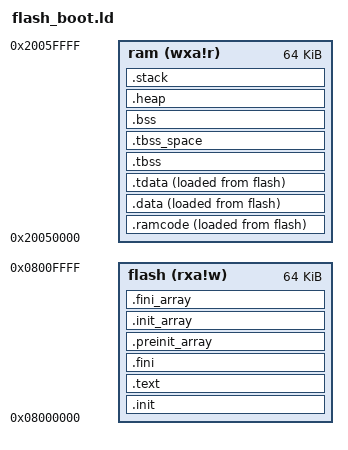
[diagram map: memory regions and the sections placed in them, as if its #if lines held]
/**
 ******************************************************************************
 * @file      gcc_riscv32.ld
 * @author    ListenAI application team
 * @brief     Linker script
 *                      8Mbytes     FLASH
 *                      16Kbytes    DTCMRAM
 *                      16Kbytes    ITCMRAM
 *                      128Kbytes   RAM
 *
 *            Set heap size, stack size and stack location according
 *            to application requirements.
 *
 *            Set memory bank area and size if external memory is used
 ******************************************************************************
 * @attentionsss
 *
 * <h2><center>&copy; Copyright (c) 2021 ListenAI.
 * All rights reserved.</center></h2>
 *
 * This software component is licensed by ListenAI under BSD 3-Clause license,
 * the "License"; You may not use this file except in compliance with the
 * License. You may obtain a copy of the License at:
 *                        opensource.org/licenses/BSD-3-Clause
 *
 ******************************************************************************
 */

OUTPUT_ARCH( "riscv" )

ENTRY( _start )

#if FLASH_ENC_ALL==1
FLASH_BASE = 0x08000000;
#else
FLASH_BASE = 0x30000000;
#endif

MEMORY
{
  flash (rxa!w) : ORIGIN = FLASH_BASE, LENGTH = 64K
  ram (wxa!r) : ORIGIN = 0x20050000, LENGTH = 64K
}

REGION_ALIAS("ROM", flash)
REGION_ALIAS("RAM", ram)
REGION_ALIAS("DATA_LMA", flash)

SECTIONS
{
  /* To provide symbol __STACK_SIZE, __HEAP_SIZE and __SMP_CPU_CNT */
  PROVIDE(__STACK_SIZE = 4K);
  PROVIDE(__HEAP_SIZE = 4K);
  PROVIDE(__SMP_CPU_CNT = 1);
  __TOT_STACK_SIZE = __STACK_SIZE * __SMP_CPU_CNT;

  .init           :
  {
    KEEP(*(.OTA_HEADER)) /* OTA header */
    KEEP(*(.SIGN_DATA))  /* signature data */
    . = ALIGN(512);
    /* vector table locate at ROM */
    *(.vtable)
    *(.vtable_s)
    KEEP (*(SORT_NONE(.init)))
    . = ALIGN(4);
  } >ROM AT>ROM

  /* Code section located at ROM */
  .text           :
  {
    *(.text.unlikely .text.unlikely.*)
    *(.text.startup .text.startup.*)
    *(.text .text.*)
    *(.gnu.linkonce.t.*)
    /* readonly data placed in ROM */
    . = ALIGN(8);
    *(.srodata.cst16)
    *(.srodata.cst8)
    *(.srodata.cst4)
    *(.srodata.cst2)
    *(.srodata .srodata.*)
    *(.rdata)
    *(.ROM_DATA)
    *(.gnu.linkonce.r.*)
    /* below sections are used for rt-thread */
    . = ALIGN(4);
    __rt_init_start = .;
    KEEP(*(SORT(.rti_fn*)))
    __rt_init_end = .;
    . = ALIGN(4);
    __fsymtab_start = .;
    KEEP(*(FSymTab))
    __fsymtab_end = .;
    . = ALIGN(4);
    __vsymtab_start = .;
    KEEP(*(VSymTab))
    __vsymtab_end = .;
  } >ROM AT>ROM

  .fini           :
  {
    KEEP (*(SORT_NONE(.fini)))
  } >ROM AT>ROM

  .preinit_array  :
  {
    PROVIDE_HIDDEN (__preinit_array_start = .);
    KEEP (*(.preinit_array))
    PROVIDE_HIDDEN (__preinit_array_end = .);
  } >ROM AT>ROM

  .init_array     :
  {
    PROVIDE_HIDDEN (__init_array_start = .);
    KEEP (*(SORT_BY_INIT_PRIORITY(.init_array.*) SORT_BY_INIT_PRIORITY(.ctors.*)))
    KEEP (*(.init_array EXCLUDE_FILE (*crtbegin.o *crtbegin?.o *crtend.o *crtend?.o ) .ctors))
    PROVIDE_HIDDEN (__init_array_end = .);
  } >ROM AT>ROM

  .fini_array     :
  {
    PROVIDE_HIDDEN (__fini_array_start = .);
    KEEP (*(SORT_BY_INIT_PRIORITY(.fini_array.*) SORT_BY_INIT_PRIORITY(.dtors.*)))
    KEEP (*(.fini_array EXCLUDE_FILE (*crtbegin.o *crtbegin?.o *crtend.o *crtend?.o ) .dtors))
    PROVIDE_HIDDEN (__fini_array_end = .);
  } >ROM AT>ROM

  PROVIDE(_rom_code_start = ORIGIN(ROM));
  PROVIDE(_rom_code_end   = .);
  .ramcode        : ALIGN(8)
  {
    *(.rodata .rodata.*)
    . = ALIGN(8);
  } >RAM AT>DATA_LMA

  PROVIDE( _ram_code_start = ADDR(.ramcode));
  PROVIDE( _ram_code_end  = .);
  PROVIDE( _ilm_lma = LOADADDR(.text) );
  PROVIDE( _ilm = ADDR(.text) );
  PROVIDE( _eilm = . );
  PROVIDE( _text_lma = LOADADDR(.ramcode) );
  PROVIDE( _text = ADDR(.ramcode) );
  PROVIDE (_etext = .);
  PROVIDE (__etext = .);
  PROVIDE (etext = .);

  .data            : ALIGN(8)
  {
    KEEP(*(.data.ctest*))
    *(.data .data.*)
    *(.gnu.linkonce.d.*)
    . = ALIGN(8);
    PROVIDE( __global_pointer$ = . + 0x800 );
    *(.sdata .sdata.* .sdata*)
    *(.gnu.linkonce.s.*)
    /* readonly data placed in RAM for access speed */
    . = ALIGN(8);
    *(.gnu.linkonce.r.*)
    /* below sections are used for rt-thread */
    . = ALIGN(4);
    __rt_init_start = .;
    KEEP(*(SORT(.rti_fn*)))
    __rt_init_end = .;
    . = ALIGN(4);
    __fsymtab_start = .;
    KEEP(*(FSymTab))
    __fsymtab_end = .;
    . = ALIGN(4);
    __vsymtab_start = .;
    KEEP(*(VSymTab))
    __vsymtab_end = .;
    . = ALIGN(8);
  } >RAM AT>DATA_LMA

  .tdata           : ALIGN(8)
  {
    PROVIDE( __tls_base = . );
    *(.tdata .tdata.* .gnu.linkonce.td.*)
  } >RAM AT>DATA_LMA

  PROVIDE( _data_lma = LOADADDR(.data) );
  PROVIDE( _data = ADDR(.data) );
  PROVIDE( _edata = . );
  PROVIDE( edata = . );

  PROVIDE( _fbss = . );
  PROVIDE( __bss_start = . );

  .tbss (NOLOAD)   : ALIGN(8)
  {
    *(.tbss .tbss.* .gnu.linkonce.tb.*)
    *(.tcommon)
    PROVIDE( __tls_end = . );
  } >RAM AT>RAM

  .tbss_space (NOLOAD) : ALIGN(8)
  {
    . = . + SIZEOF(.tbss);
  } >RAM AT>RAM

  .bss (NOLOAD)   : ALIGN(8)
  {
    *(.sbss*)
    *(.gnu.linkonce.sb.*)
    *(.bss .bss.*)
    *(.gnu.linkonce.b.*)
    *(COMMON)
    . = ALIGN(4);
  } >RAM AT>RAM

  PROVIDE( _end = . );
  PROVIDE( end = . );

  /* Nuclei C Runtime Library requirements:
   * 1. heap need to be align at 16 bytes
   * 2. __heap_start and __heap_end symbol need to be defined
   * 3. reserved at least __HEAP_SIZE space for heap
   */
  .heap (NOLOAD)   : ALIGN(16)
  {
    . = ALIGN(16);
    PROVIDE( __heap_start = . );
    . += __HEAP_SIZE;
    . = ALIGN(16);
    PROVIDE( __heap_limit = . );
  } >RAM AT>RAM

  .stack ORIGIN(RAM) + LENGTH(RAM) - __TOT_STACK_SIZE (NOLOAD) :
  {
    . = ALIGN(16);
    PROVIDE( _heap_end = . );
    PROVIDE( __heap_end = . );
    PROVIDE( __StackLimit = . );
    PROVIDE( __StackBottom = . );
    . += __TOT_STACK_SIZE;
    . = ALIGN(16);
    PROVIDE( __StackTop = . );
    PROVIDE( _sp = . );
  } >RAM AT>RAM
}
  
  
